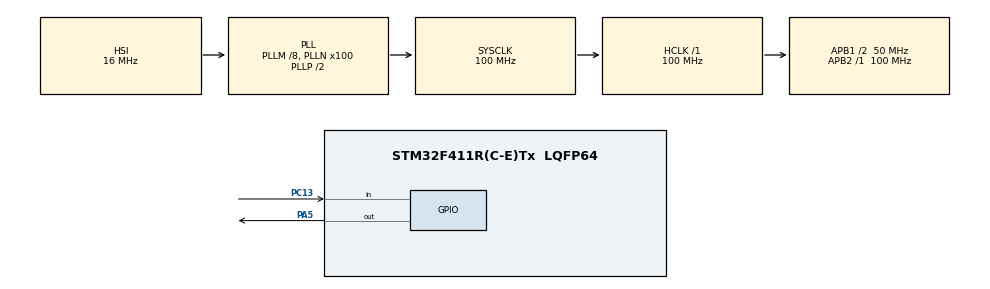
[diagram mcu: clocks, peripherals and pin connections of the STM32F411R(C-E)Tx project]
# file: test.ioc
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Mcu.Family=STM32F4
TIM10.Prescaler=10000-1
RCC.CortexFreq_Value=100000000
PA14.GPIO_Label=TCK
RCC.APB1CLKDivider=RCC_HCLK_DIV2
RCC.SYSCLKSource=RCC_SYSCLKSOURCE_PLLCLK
ProjectManager.StackSize=0x400
PA13.Signal=SYS_JTMS-SWDIO
ProjectManager.TargetToolchain=STM32CubeIDE
RCC.HCLKFreq_Value=100000000
RCC.APB2TimFreq_Value=100000000
VP_TIM10_VS_ClockSourceINT.Mode=Enable_Timer
RCC.LSE_VALUE=32768
RCC.AHBFreq_Value=100000000
PA5.Signal=GPIO_Output
RCC.HSE_VALUE=8000000
board=custom
PC13-ANTI_TAMP.Signal=GPIO_Input
RCC.VCOOutputFreq_Value=200000000
TIM10.Period=99
RCC.APB2Freq_Value=100000000
PA14.Mode=Serial_Wire
PA13.Mode=Serial_Wire
Mcu.Name=STM32F411R(C-E)Tx
RCC.FLatency-AdvancedSettings=FLASH_LATENCY_3
RCC.48MHZClocksFreq_Value=50000000
RCC.SYSCLKFreq_VALUE=100000000
Mcu.Package=LQFP64
PA14.Signal=SYS_JTCK-SWCLK
ProjectManager.HeapSize=0x200
NVIC.TIM1_UP_TIM10_IRQn=true\:0\:0\:false\:false\:true\:true\:true
RCC.HSI_VALUE=16000000
NVIC.PriorityGroup=NVIC_PRIORITYGROUP_0
RCC.PLLM=8
RCC.PLLN=100
RCC.APB1TimFreq_Value=100000000
RCC.APB1Freq_Value=50000000

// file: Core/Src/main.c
/* USER CODE BEGIN Header */
/**
  ******************************************************************************
  * @file           : main.c
  * @brief          : Main program body
  ******************************************************************************
  * @attention
  *
  * <h2><center>&copy; Copyright (c) 2021 STMicroelectronics.
  * All rights reserved.</center></h2>
  *
  * This software component is licensed by ST under BSD 3-Clause license,
  * the "License"; You may not use this file except in compliance with the
  * License. You may obtain a copy of the License at:
  *                        opensource.org/licenses/BSD-3-Clause
  *
  ******************************************************************************
  */
/* USER CODE END Header */
#include "main.h"

TIM_HandleTypeDef htim10;

/* USER CODE BEGIN PV */
enum {KeyCheck=0,KeyComfirm,KeyRelease};
int KeyState = 0;
int KeyFlag = 0;
/* USER CODE END PV */

void SystemClock_Config(void);
static void MX_GPIO_Init(void);
static void MX_TIM10_Init(void);

int main(void)
{

  /* MCU Configuration--------------------------------------------------------*/

  /* Reset of all peripherals, Initializes the Flash interface and the Systick. */
  HAL_Init();

  /* Configure the system clock */
  SystemClock_Config();

  /* Initialize all configured peripherals */
  MX_GPIO_Init();
  MX_TIM10_Init();
  /* USER CODE BEGIN 2 */
  HAL_TIM_Base_Start_IT(&htim10);
  /* USER CODE END 2 */

  /* Infinite loop */
  while (1)
  {

    /* USER CODE BEGIN 3 */
	  if (KeyFlag == 1)
	  {
		  KeyFlag = 0;
		  HAL_GPIO_TogglePin(GPIOA,GPIO_PIN_5);
	  }
  }

  /* USER CODE END 3 */
}

void SystemClock_Config(void)
{
  RCC_OscInitTypeDef RCC_OscInitStruct = {0};
  RCC_ClkInitTypeDef RCC_ClkInitStruct = {0};

  /** Configure the main internal regulator output voltage
  */
  __HAL_RCC_PWR_CLK_ENABLE();
  __HAL_PWR_VOLTAGESCALING_CONFIG(PWR_REGULATOR_VOLTAGE_SCALE1);
  /** Initializes the RCC Oscillators according to the specified parameters
  * in the RCC_OscInitTypeDef structure.
  */
  RCC_OscInitStruct.OscillatorType = RCC_OSCILLATORTYPE_HSI;
  RCC_OscInitStruct.HSIState = RCC_HSI_ON;
  RCC_OscInitStruct.HSICalibrationValue = RCC_HSICALIBRATION_DEFAULT;
  RCC_OscInitStruct.PLL.PLLState = RCC_PLL_ON;
  RCC_OscInitStruct.PLL.PLLSource = RCC_PLLSOURCE_HSI;
  RCC_OscInitStruct.PLL.PLLM = 8;
  RCC_OscInitStruct.PLL.PLLN = 100;
  RCC_OscInitStruct.PLL.PLLP = RCC_PLLP_DIV2;
  RCC_OscInitStruct.PLL.PLLQ = 4;
  if (HAL_RCC_OscConfig(&RCC_OscInitStruct) != HAL_OK)
  {
    Error_Handler();
  }
  /** Initializes the CPU, AHB and APB buses clocks
  */
  RCC_ClkInitStruct.ClockType = RCC_CLOCKTYPE_HCLK|RCC_CLOCKTYPE_SYSCLK
                              |RCC_CLOCKTYPE_PCLK1|RCC_CLOCKTYPE_PCLK2;
  RCC_ClkInitStruct.SYSCLKSource = RCC_SYSCLKSOURCE_PLLCLK;
  RCC_ClkInitStruct.AHBCLKDivider = RCC_SYSCLK_DIV1;
  RCC_ClkInitStruct.APB1CLKDivider = RCC_HCLK_DIV2;
  RCC_ClkInitStruct.APB2CLKDivider = RCC_HCLK_DIV1;

  if (HAL_RCC_ClockConfig(&RCC_ClkInitStruct, FLASH_LATENCY_3) != HAL_OK)
  {
    Error_Handler();
  }
}

static void MX_TIM10_Init(void)
{

  htim10.Instance = TIM10;
  htim10.Init.Prescaler = 10000-1;
  htim10.Init.CounterMode = TIM_COUNTERMODE_UP;
  htim10.Init.Period = 99;
  htim10.Init.ClockDivision = TIM_CLOCKDIVISION_DIV1;
  htim10.Init.AutoReloadPreload = TIM_AUTORELOAD_PRELOAD_DISABLE;
  if (HAL_TIM_Base_Init(&htim10) != HAL_OK)
  {
    Error_Handler();
  }

}

static void MX_GPIO_Init(void)
{
  GPIO_InitTypeDef GPIO_InitStruct = {0};

  /* GPIO Ports Clock Enable */
  __HAL_RCC_GPIOC_CLK_ENABLE();
  __HAL_RCC_GPIOA_CLK_ENABLE();

  /*Configure GPIO pin Output Level */
  HAL_GPIO_WritePin(GPIOA, GPIO_PIN_5, GPIO_PIN_RESET);

  /*Configure GPIO pin : PC13 */
  GPIO_InitStruct.Pin = GPIO_PIN_13;
  GPIO_InitStruct.Mode = GPIO_MODE_INPUT;
  GPIO_InitStruct.Pull = GPIO_NOPULL;
  HAL_GPIO_Init(GPIOC, &GPIO_InitStruct);

  /*Configure GPIO pin : PA5 */
  GPIO_InitStruct.Pin = GPIO_PIN_5;
  GPIO_InitStruct.Mode = GPIO_MODE_OUTPUT_PP;
  GPIO_InitStruct.Pull = GPIO_NOPULL;
  GPIO_InitStruct.Speed = GPIO_SPEED_FREQ_LOW;
  HAL_GPIO_Init(GPIOA, &GPIO_InitStruct);

}

/* USER CODE BEGIN 4 */
void HAL_TIM_PeriodElapsedCallback(TIM_HandleTypeDef *htim)
{
	if(htim->Instance == TIM10)
	{
		switch (KeyState){
		case KeyCheck:
		{
			if (HAL_GPIO_ReadPin(GPIOC,GPIO_PIN_13) == GPIO_PIN_RESET)
				KeyState = KeyComfirm;
			else
				KeyState = KeyCheck;
			break;
		}
		case KeyComfirm:
		{
			if (HAL_GPIO_ReadPin(GPIOC,GPIO_PIN_13) == GPIO_PIN_RESET)
				KeyState = KeyRelease;
			else
				KeyState = KeyCheck;
			KeyFlag = 1;
			break;
		}
		case KeyRelease:
		{
			if (HAL_GPIO_ReadPin(GPIOC,GPIO_PIN_13) == GPIO_PIN_SET)
				KeyState = KeyCheck;
			else
				KeyState = KeyRelease;
			break;
		}
		default: break;
		}
	}
}
/* USER CODE END 4 */

void Error_Handler(void)
{
  __disable_irq();
  while (1)
  {
  }
}

/************************ (C) COPYRIGHT STMicroelectronics *****END OF FILE****/
